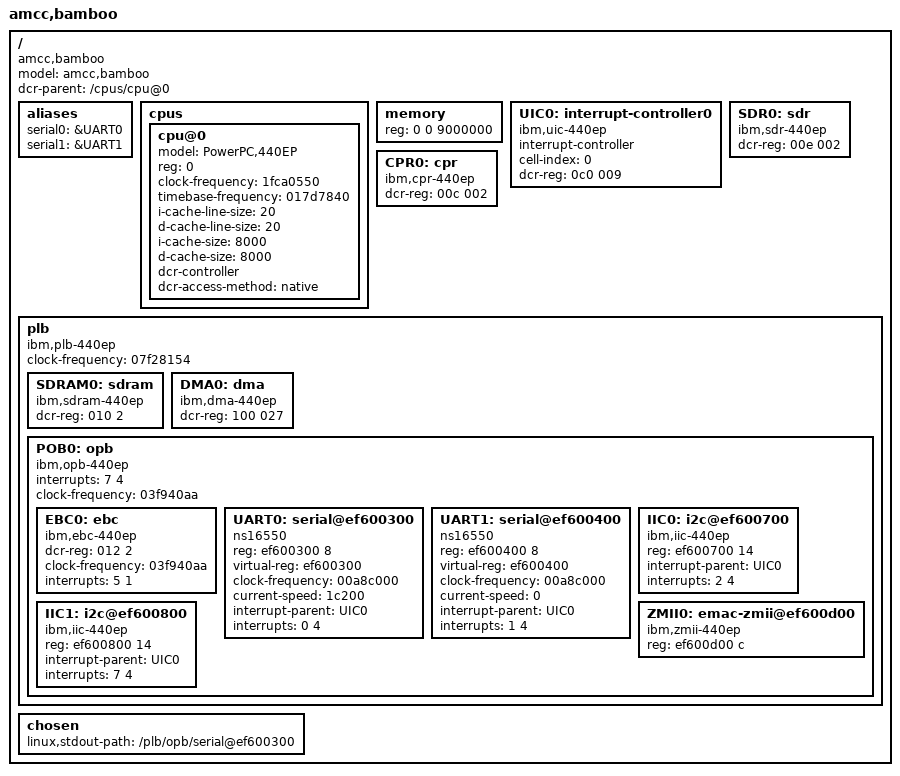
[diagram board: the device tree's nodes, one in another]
/*
 * Device Tree Source for AMCC Bamboo
 *
 * Copyright (c) 2006, 2007 IBM Corp.
 * Josh Boyer <jwboyer@linux.vnet.ibm.com>
 *
 * This file is licensed under the terms of the GNU General Public
 * License version 2.  This program is licensed "as is" without
 * any warranty of any kind, whether express or implied.
 */

/ {
	#address-cells = <2>;
	#size-cells = <1>;
	model = "amcc,bamboo";
	compatible = "amcc,bamboo";
	dcr-parent = <&/cpus/cpu@0>;

	aliases {
		serial0 = &UART0;
		serial1 = &UART1;
	};

	cpus {
		#address-cells = <1>;
		#size-cells = <0>;

		cpu@0 {
			device_type = "cpu";
			model = "PowerPC,440EP";
			reg = <0>;
			clock-frequency = <1fca0550>;
			timebase-frequency = <017d7840>;
			i-cache-line-size = <20>;
			d-cache-line-size = <20>;
			i-cache-size = <8000>;
			d-cache-size = <8000>;
			dcr-controller;
			dcr-access-method = "native";
		};
	};

	memory {
		device_type = "memory";
		reg = <0 0 9000000>;
	};

	UIC0: interrupt-controller0 {
		compatible = "ibm,uic-440ep","ibm,uic";
		interrupt-controller;
		cell-index = <0>;
		dcr-reg = <0c0 009>;
		#address-cells = <0>;
		#size-cells = <0>;
		#interrupt-cells = <2>;
	};
/*
	UIC1: interrupt-controller1 {
		compatible = "ibm,uic-440ep","ibm,uic";
		interrupt-controller;
		cell-index = <1>;
		dcr-reg = <0d0 009>;
		#address-cells = <0>;
		#size-cells = <0>;
		#interrupt-cells = <2>;
		interrupts = <1e 4 1f 4>;
		interrupt-parent = <&UIC0>;
	};
*/

	SDR0: sdr {
		compatible = "ibm,sdr-440ep";
		dcr-reg = <00e 002>;
	};

	CPR0: cpr {
		compatible = "ibm,cpr-440ep";
		dcr-reg = <00c 002>;
	};

	plb {
		compatible = "ibm,plb-440ep", "ibm,plb-440gp", "ibm,plb4";
		#address-cells = <2>;
		#size-cells = <1>;
		ranges;
		clock-frequency = <07f28154>;

		SDRAM0: sdram {
			compatible = "ibm,sdram-440ep", "ibm,sdram-405gp";
			dcr-reg = <010 2>;
		};

		DMA0: dma {
			compatible = "ibm,dma-440ep", "ibm,dma-440gp";
			dcr-reg = <100 027>;
		};

		POB0: opb {
			compatible = "ibm,opb-440ep", "ibm,opb-440gp", "ibm,opb";
			#address-cells = <1>;
			#size-cells = <1>;
			/* Bamboo is oddball in the 44x world and doesn't use the ERPN
			 * bits.
			 */
			ranges = <00000000 0 00000000 80000000
			          80000000 0 80000000 80000000>;
			/* interrupt-parent = <&UIC1>; */
			interrupts = <7 4>;
			clock-frequency = <03f940aa>;

			EBC0: ebc {
				compatible = "ibm,ebc-440ep", "ibm,ebc-440gp", "ibm,ebc";
				dcr-reg = <012 2>;
				#address-cells = <2>;
				#size-cells = <1>;
				clock-frequency = <03f940aa>;
				interrupts = <5 1>;
			/* interrupt-parent = <&UIC1>; */
			};

			UART0: serial@ef600300 {
				device_type = "serial";
				compatible = "ns16550";
				reg = <ef600300 8>;
				virtual-reg = <ef600300>;
				clock-frequency = <00a8c000>;
				current-speed = <1c200>;
				interrupt-parent = <&UIC0>;
				interrupts = <0 4>;
			};

			UART1: serial@ef600400 {
				device_type = "serial";
				compatible = "ns16550";
				reg = <ef600400 8>;
				virtual-reg = <ef600400>;
				clock-frequency = <00a8c000>;
				current-speed = <0>;
				interrupt-parent = <&UIC0>;
				interrupts = <1 4>;
			};
/*
			UART2: serial@ef600500 {
				device_type = "serial";
				compatible = "ns16550";
				reg = <ef600500 8>;
				virtual-reg = <ef600500>;
				clock-frequency = <0>;
				current-speed = <0>;
				interrupt-parent = <&UIC0>;
				interrupts = <3 4>;
			};

			UART3: serial@ef600600 {
				device_type = "serial";
				compatible = "ns16550";
				reg = <ef600600 8>;
				virtual-reg = <ef600600>;
				clock-frequency = <0>;
				current-speed = <0>;
				interrupt-parent = <&UIC0>;
				interrupts = <4 4>;
			};

*/
			IIC0: i2c@ef600700 {
				device_type = "i2c";
				compatible = "ibm,iic-440ep", "ibm,iic-440gp", "ibm,iic";
				reg = <ef600700 14>;
				interrupt-parent = <&UIC0>;
				interrupts = <2 4>;
			};

			IIC1: i2c@ef600800 {
				device_type = "i2c";
				compatible = "ibm,iic-440ep", "ibm,iic-440gp", "ibm,iic";
				reg = <ef600800 14>;
				interrupt-parent = <&UIC0>;
				interrupts = <7 4>;
			};

			ZMII0: emac-zmii@ef600d00 {
				device_type = "zmii-interface";
				compatible = "ibm,zmii-440ep", "ibm,zmii-440gp", "ibm,zmii";
				reg = <ef600d00 c>;
			};

		};

	};

	chosen {
		linux,stdout-path = "/plb/opb/serial@ef600300";
	};
};
